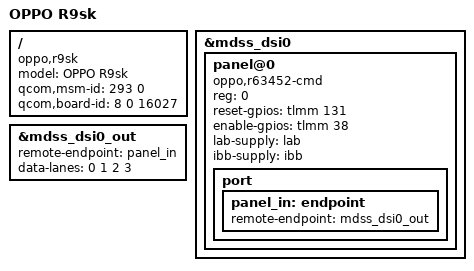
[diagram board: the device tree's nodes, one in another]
// SPDX-License-Identifier: BSD-3-Clause
/*
 * OPPO R9sk (16027) —— MSM8953
 *
 * board-id <8 0 16027>。本机型是用户手上那台（16027）。
 */

/dts-v1/;

#include "msm8953-oppo-common.dtsi"

/ {
	model = "OPPO R9sk";
	compatible = "oppo,r9sk", "qcom,msm8953";

	qcom,msm-id = <293 0>;
	qcom,board-id = <8 0 16027>;
};

/*
 * 16027 的面板：JDI R63452（command-mode TFT/LCD）
 *
 * 参数来源（本仓库 4.19 的 oppo-msm8953/16027/msm8953-mtp.dtsi）：
 *   qcom,platform-enable-gpio   = <&tlmm 38  0>
 *   qcom,platform-bklight-en-gpio = <&tlmm 34 0>   ← 背光使能，暂未接
 *   qcom,platform-reset-gpio    = <&tlmm 131 0>
 * LCD 偏压走 PMI8950 的 LAB/IBB（qcom,qpnp-labibb-mode = "lcd"）。
 */
&mdss_dsi0 {
	panel@0 {
		compatible = "oppo,r63452-cmd";
		reg = <0>;

		reset-gpios = <&tlmm 131 GPIO_ACTIVE_HIGH>;
		enable-gpios = <&tlmm 38 GPIO_ACTIVE_HIGH>;

		lab-supply = <&lab>;
		ibb-supply = <&ibb>;

		port {
			panel_in: endpoint {
				remote-endpoint = <&mdss_dsi0_out>;
			};
		};
	};
};

/*
 * 面板 graph 必须**双向**连接。
 *
 * msm8953.dtsi 里 mdss_dsi0 的 port@1/endpoint 是空的（没有
 * remote-endpoint），而这里的 panel_in 指向它 —— 单向链接。
 *
 * 后果：devm_drm_of_get_bridge() → drm_of_find_panel_or_bridge()
 * → of_graph_get_remote_node(np, 1, 0) 读不到 remote-endpoint
 * 就返回 NULL，最终 -ENODEV；dsi_bind() 直接失败 →
 * component bind 失败 → **DSI 起不来、屏幕不亮**。
 *
 * dtc 其实会报 warning：
 *   Warning (graph_endpoint): graph connection to node
 *   '.../dsi@1a94000/ports/port@1/endpoint' is not bidirectional
 *
 * 上游所有用 panel 的板子都写了双向（对照 msm8916-samsung-a3u-eur.dts）。
 * R63452 / EA8064 都是 4 lane。
 */
&mdss_dsi0_out {
	remote-endpoint = <&panel_in>;
	data-lanes = <0 1 2 3>;
};
